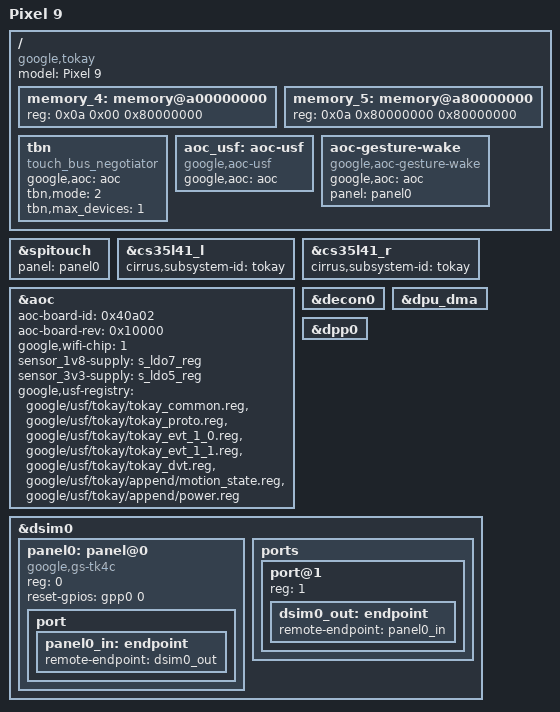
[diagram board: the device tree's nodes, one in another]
// SPDX-License-Identifier: GPL-2.0-only
/*
 * Pixel 9 (tokay) Device Tree
 *
 * Copyright 2025 Trijal Saha - <trijalsaha2012@gmail.com>
 */

/dts-v1/;

#include "zumapro-pixel-common.dtsi"
#include "zumapro-caimito-bcm4390.dtsi"
#include "zumapro-caimito-s5400.dtsi"
#include "zumapro-caimito-cs35l41.dtsi"

/ {
	model = "Pixel 9";
	compatible = "google,tokay", "google,zumapro-tokay", "google,zumapro";

	memory_4: memory@a00000000 {
		device_type = "memory";
		reg = <0x0a 0x00 0x80000000>;
	};

	memory_5: memory@a80000000 {
		device_type = "memory";
		reg = <0x0a 0x80000000 0x80000000>;
	};
};

/* Board identity the AOC firmware reads at boot. */
/*
 * The Halo DSP speaker-protection tuning is specific to this board's drivers
 * and to each channel, so the firmware has to be named for both.  This is what
 * wm_adsp interpolates as the system name: the amplifiers ask for
 * cirrus/cs35l41-dsp1-spk-prot-tokay.wmfw, and for a tuning of the same stem
 * with "-r" appended on the right-hand amplifier, which carries the prefix.
 */
/*
 * Follow the panel, so the controller enters low-power gesture mode when the
 * display blanks rather than only when the whole system suspends. Without a
 * "panel" property drm_panel_add_follower() has nothing to look up and fails
 * with -ENODEV, which costs every wake gesture while the AP is awake with the
 * display off - which is exactly when they are wanted.
 *
 * It cannot live in the common dtsi: only the boards that declare a panel0
 * could resolve the reference.
 */
&spitouch {
	panel = <&panel0>;
};

&cs35l41_l {
	cirrus,subsystem-id = "tokay";
};

&cs35l41_r {
	cirrus,subsystem-id = "tokay";
};

&aoc {
	aoc-board-id = <0x40a02>;
	aoc-board-rev = <0x10000>;
	google,wifi-chip = <1>;	/* BCM4390 */

	/*
	 * The rails the AoC's physical sensors hang off.  The AoC does not
	 * switch these itself, and without them its sensor stack enumerates
	 * only the fused and software sensors -- the ICM45631, magnetometer,
	 * barometer and proximity chips never answer.  Mapping matches the
	 * downstream zumapro-common.dtsi, which describes them once for every
	 * zumapro board: sensor_1v8 = L7S_SENSORS (LDO7S), sensor_3v3 =
	 * L5S_PROX (LDO5S).
	 */
	sensor_1v8-supply = <&s_ldo7_reg>;
	sensor_3v3-supply = <&s_ldo5_reg>;

	/*
	 * The sensor registry, described here rather than on a consumer,
	 * because it is one piece of AoC-global state: the IIO bridge and the
	 * wake-gesture driver both ask for it, and whichever arrives first
	 * loads it.
	 *
	 * These are the vendor .reg scripts, copied unmodified into the
	 * firmware path -- the tree under /vendor/etc/sensors/registry, layout
	 * and all.  They are named here rather than discovered, because the
	 * kernel cannot enumerate a directory to load firmware from, and
	 * because which scripts a board carries is board description.
	 *
	 * All of them are uploaded whatever the stage.  Each carries its own
	 * ?+CDT/?-CDT filter and the AoC evaluates those against the CDT
	 * composed from /chosen/plat, so the scripts for other stages exclude
	 * themselves; tokay is product A, so a stage-6 part (CDT 0x000A6100) is
	 * left with tokay_common, tokay_dvt and the two append scripts.  Order
	 * matters: the common script defines the buses and the devices, the
	 * stage script refines them, and the append scripts come last.  tokay
	 * carries no mag-DOE or wingboard scripts; it has one script per stage.
	 */
	google,usf-registry = "google/usf/tokay/tokay_common.reg",
			      "google/usf/tokay/tokay_proto.reg",
			      "google/usf/tokay/tokay_evt_1_0.reg",
			      "google/usf/tokay/tokay_evt_1_1.reg",
			      "google/usf/tokay/tokay_dvt.reg",
			      "google/usf/tokay/append/motion_state.reg",
			      "google/usf/tokay/append/power.reg";
};

/ {
	/*
	 * Touch Bus Negotiator.  tbn,mode = 2 is the AoC-channel handshake: the
	 * AP <-> AoC arbitration runs as messages over the com.google.tbn_service AoC
	 * service rather than over GPIOs, which is what the downstream tbn node
	 * describes.  One consumer, the touch controller.
	 */
	tbn: tbn {
		compatible = "touch_bus_negotiator";
		google,aoc = <&aoc>;
		tbn,mode = <2>;
		tbn,max_devices = <1>;
	};

	/*
	 * The AoC sensor hub, bridged to IIO.  No hardware is described here:
	 * the sensors live in AoC firmware behind the com.google.usf service.
	 * The registry it needs is named on the AoC node above.
	 */
	aoc_usf: aoc-usf {
		compatible = "google,aoc-usf";
		google,aoc = <&aoc>;
	};

	/*
	 * Wake gestures the AoC watches while the AP sleeps: a tap on the dark panel,
	 * and lift-to-wake, reported as KEY_WAKEUP.  Armed only while the panel it
	 * names is off.
	 */
	aoc-gesture-wake {
		compatible = "google,aoc-gesture-wake";
		google,aoc = <&aoc>;
		panel = <&panel0>;
	};
};

// &decon_autorefresh_bit {
// 	status = "okay";
// };
//
// &cont_splash_mem {
// 	// reg = <0x0 0xfac00000 (1440 * 3120 * 4)>;
// 	reg = <0x0 0xfac00000 (1080 * 2424 * 4)>;
//
// 	status = "okay";
// };
//
// &framebuffer0 {
// 	// width = <1440>;
// 	// height = <3120>;
// 	// stride = <(1440 * 4)>;
// 	width = <1080>;
// 	height = <2424>;
// 	stride = <(1080 * 4)>;
// 	format = "a8r8g8b8";
//
// 	status = "okay";
// };

/*
 * Display (DPU) bring-up for tokay.
 *
 * The DECON0/DPP/DPU-DMA/DSIM0 topology is defined in zumapro.dtsi; this
 * board section enables it and attaches the tokay panel via a minimal
 * boot-handoff panel driver (google,gs-tk4c, unlike komodo's and caiman's
 * google,<board>-panel - the driver matches the downstream panel name here).
 *
 * The bootloader initialises the DCPHY, DSIM link and panel and leaves the
 * (dual-DSC, command-mode) link streaming - that is what the simple-
 * framebuffer splash draws into. The DECON DRM stack takes over scanning its
 * own framebuffer into that running link (the DECON emits the matching
 * dual-DSC stream). Disable the simple-framebuffer (and the decon-autorefresh
 * mmio-init) before relying on the DECON output, since enabling decon0 runs
 * decon_reset() and tears the bootloader splash down.
 */
&decon0 {
	status = "okay";
};

&dpu_dma {
	status = "okay";
};

&dpp0 {
	status = "okay";
};

&dsim0 {
	status = "okay";

	panel0: panel@0 {
		compatible = "google,gs-tk4c";
		reg = <0>;
		/* DDIC reset for cold power-on (unused on boot handover) */
		reset-gpios = <&gpp0 0 GPIO_ACTIVE_HIGH>;

		port {
			panel0_in: endpoint {
				remote-endpoint = <&dsim0_out>;
			};
		};
	};

	ports {
		port@1 {
			reg = <1>;
			dsim0_out: endpoint {
				remote-endpoint = <&panel0_in>;
			};
		};
	};
};
